# ipro7 register map
Vendor: intelpro; Series: BTBLE
CPU: ipro7, little endian
Registers are 32-bit, read-write, reset 0x0 unless marked. A register's access mark holds for its fields unless they carry their own. Offsets are from the block's base; [hi:lo] are bit positions; {n}, {i} and the like mark numbered series; 'fields as' and 'values as' point back to an identical list.

## OSD_DRAW
Base 0x30047000
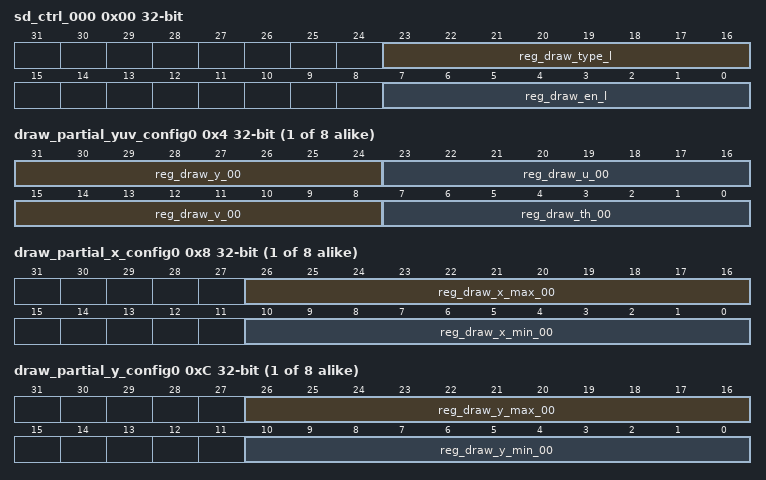
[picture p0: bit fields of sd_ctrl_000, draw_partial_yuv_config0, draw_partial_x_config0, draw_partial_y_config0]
0x00 sd_ctrl_000
  [23:16] reg_draw_type_l — Config of all layers draw type in OSD draw. MSB layer has the highest priority, LSB layer has the lowest priority. Value '1' means SOLID type, '0' means HOLLOW type.
  [7:0] reg_draw_en_l — Enable or disable draw of all layers in OSD draw. MSB layer has the highest priority, LSB layer has the lowest priority. Value '1' means enable, '0' means disable.
{0x4+0xC*i} draw_partial_yuv_config{i} (i=0..7)
  [31:24] reg_draw_y_{i:02} — Y component of draw layer{i} in OSD draw.. Range:0~255
  [23:16] reg_draw_u_{i:02} — U component of draw layer{i} in OSD draw.. Range:0~255
  [15:8] reg_draw_v_{i:02} — V component of draw layer{i} in OSD draw.. Range:0~255
  [7:0] reg_draw_th_{i:02} — Thickness of line of draw layer{i} in OSD draw.. Range:0~255. MUST be EVEN
{0x8+0xC*i} draw_partial_x_config{i} (i=0..7)
  [26:16] reg_draw_x_max_{i:02} — End X point of draw layer{i} in OSD draw.. MUST be ODD
  [10:0] reg_draw_x_min_{i:02} — Start X point of draw layer{i} in OSD draw.. MUST be EVEN
{0xC+0xC*i} draw_partial_y_config{i} (i=0..7)
  [26:16] reg_draw_y_max_{i:02} — End Y point of draw layer{i} in OSD draw.. MUST be ODD
  [10:0] reg_draw_y_min_{i:02} — Start Y point of draw layer{i} in OSD draw.. MUST be EVEN
0xF0 draw_sw_shd
  [0] cr_sw_shd

## WDR
Base 0x3004E000
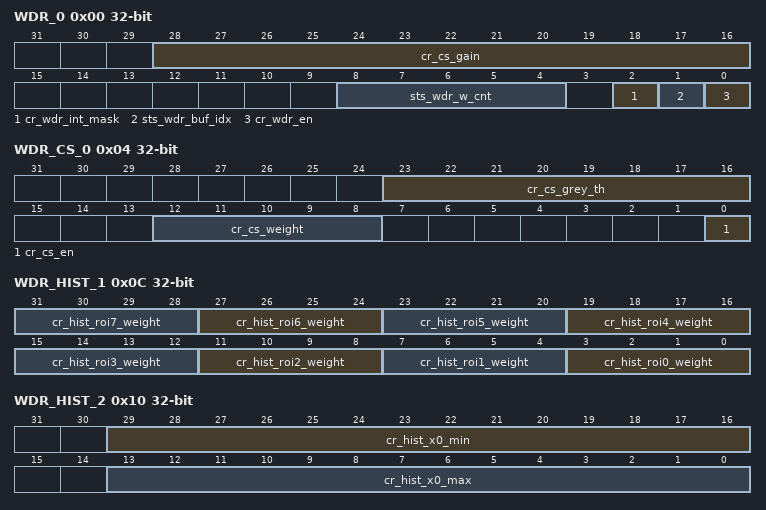
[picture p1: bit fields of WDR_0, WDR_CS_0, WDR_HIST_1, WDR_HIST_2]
0x00 WDR_0 (reset mask 0xFFFFFE0D)
  [28:16] cr_cs_gain — chroma suppression gain
  [8:4] sts_wdr_w_cnt ro — write buf index
  [2] cr_wdr_int_mask — Interrupt mask
  [1] sts_wdr_buf_idx ro — read buf index
  [0] cr_wdr_en — 0' - disable wdr, '1' -enable
0x04 WDR_CS_0
  [23:16] cr_cs_grey_th — chroma suppression grey threshold
  [12:8] cr_cs_weight — chroma suppression weight
  [0] cr_cs_en — 0' - disable chroma suppression, '1' -enable
0x08 WDR_HIST_0
  [7:0] cr_hist_roi_en — enable histogram of ROI 7-0
0x0C WDR_HIST_1
  [4n+3:4n] cr_hist_roi{n}_weight (n=0..7) — weight of ROI {n}
0x10 WDR_HIST_2
  [29:16] cr_hist_x0_min — left 1alue of x axis in ROI 0
  [13:0] cr_hist_x0_max — right 1alue of x axis in ROI 0
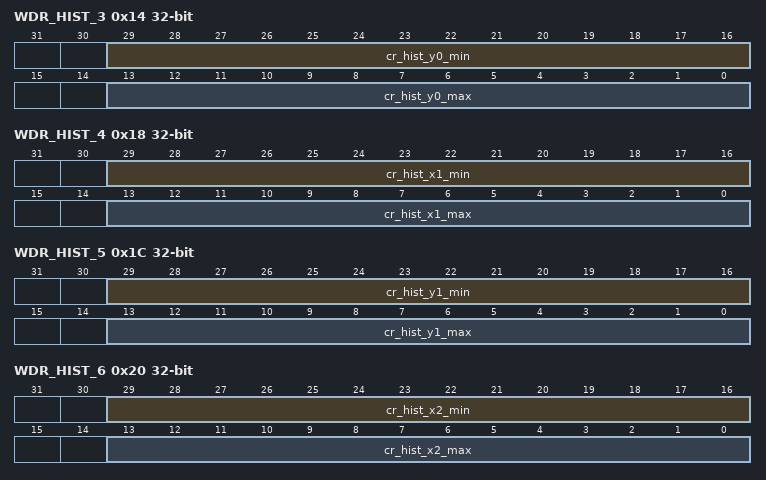
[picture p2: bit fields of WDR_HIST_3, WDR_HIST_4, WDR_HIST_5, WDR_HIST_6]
0x14 WDR_HIST_3
  [29:16] cr_hist_y0_min — bottom 1alue of x axis in ROI 0
  [13:0] cr_hist_y0_max — top 1alue of x axis in ROI 0
0x18 WDR_HIST_4
  [29:16] cr_hist_x1_min — left 1alue of x axis in ROI 1
  [13:0] cr_hist_x1_max — right 1alue of x axis in ROI 1
0x1C WDR_HIST_5
  [29:16] cr_hist_y1_min — bottom 1alue of x axis in ROI 1
  [13:0] cr_hist_y1_max — top 1alue of x axis in ROI 1
0x20 WDR_HIST_6
  [29:16] cr_hist_x2_min — left 1alue of x axis in ROI 2
  [13:0] cr_hist_x2_max — right 1alue of x axis in ROI 2
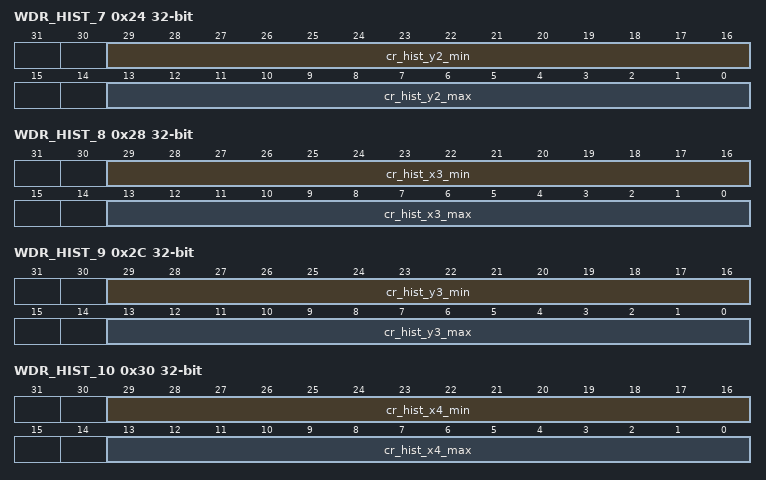
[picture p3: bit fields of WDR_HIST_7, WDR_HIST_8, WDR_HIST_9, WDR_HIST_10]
0x24 WDR_HIST_7
  [29:16] cr_hist_y2_min — bottom 1alue of x axis in ROI 2
  [13:0] cr_hist_y2_max — top 1alue of x axis in ROI 2
0x28 WDR_HIST_8
  [29:16] cr_hist_x3_min — left 1alue of x axis in ROI 3
  [13:0] cr_hist_x3_max — right 1alue of x axis in ROI 3
0x2C WDR_HIST_9
  [29:16] cr_hist_y3_min — bottom 1alue of x axis in ROI 3
  [13:0] cr_hist_y3_max — top 1alue of x axis in ROI 3
0x30 WDR_HIST_10
  [29:16] cr_hist_x4_min — left 1alue of x axis in ROI 4
  [13:0] cr_hist_x4_max — right 1alue of x axis in ROI 4
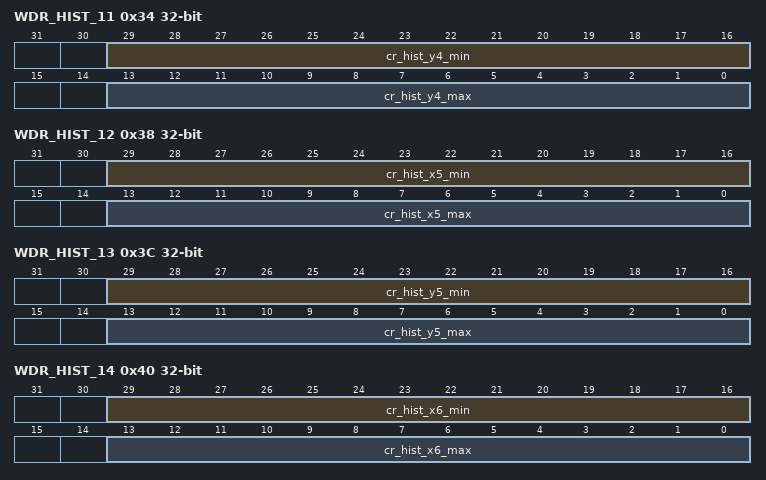
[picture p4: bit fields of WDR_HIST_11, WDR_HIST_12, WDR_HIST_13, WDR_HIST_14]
0x34 WDR_HIST_11
  [29:16] cr_hist_y4_min — bottom 1alue of x axis in ROI 4
  [13:0] cr_hist_y4_max — top 1alue of x axis in ROI 4
0x38 WDR_HIST_12
  [29:16] cr_hist_x5_min — left 1alue of x axis in ROI 5
  [13:0] cr_hist_x5_max — right 1alue of x axis in ROI 5
0x3C WDR_HIST_13
  [29:16] cr_hist_y5_min — bottom 1alue of x axis in ROI 5
  [13:0] cr_hist_y5_max — top 1alue of x axis in ROI 5
0x40 WDR_HIST_14
  [29:16] cr_hist_x6_min — left 1alue of x axis in ROI 6
  [13:0] cr_hist_x6_max — right 1alue of x axis in ROI 6
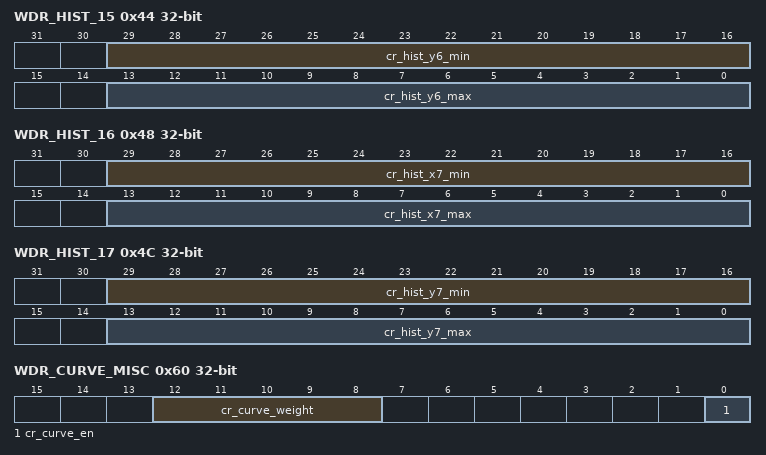
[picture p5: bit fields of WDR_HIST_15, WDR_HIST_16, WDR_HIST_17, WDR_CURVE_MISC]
0x44 WDR_HIST_15
  [29:16] cr_hist_y6_min — bottom 1alue of x axis in ROI 6
  [13:0] cr_hist_y6_max — top 1alue of x axis in ROI 6
0x48 WDR_HIST_16
  [29:16] cr_hist_x7_min — left 1alue of x axis in ROI 7
  [13:0] cr_hist_x7_max — right 1alue of x axis in ROI 7
0x4C WDR_HIST_17
  [29:16] cr_hist_y7_min — bottom 1alue of x axis in ROI 7
  [13:0] cr_hist_y7_max — top 1alue of x axis in ROI 7
0x60 WDR_CURVE_MISC
  [12:8] cr_curve_weight — wdr curve weight
  [0] cr_curve_en — enable wdr curve
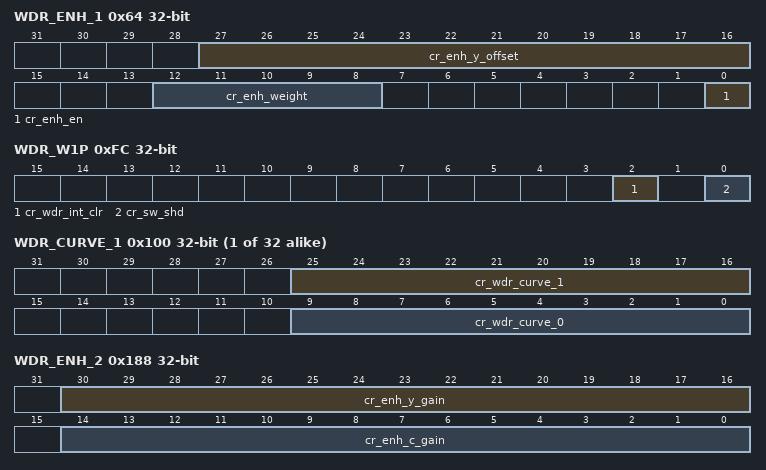
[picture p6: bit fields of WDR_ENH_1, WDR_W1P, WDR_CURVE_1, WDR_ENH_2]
0x64 WDR_ENH_1
  [27:16] cr_enh_y_offset — luma offset of post enhancement
  [12:8] cr_enh_weight — post enhancement weight
  [0] cr_enh_en — enable post enhancement
0xFC WDR_W1P
  [2] cr_wdr_int_clr wo — WDR interrupt clear
  [0] cr_sw_shd wo — SW force shadow
{0xFC+4i} WDR_CURVE_{i} (i=1..32)
  [25:16] cr_wdr_curve_{2i-1} — wdr curve {2i-1}
  [9:0] cr_wdr_curve_{2i-2} — wdr curve {2i-2}
0x188 WDR_ENH_2
  [30:16] cr_enh_y_gain — luma gain of post enhancement
  [14:0] cr_enh_c_gain — chroma gain of post enhancement

## AE_HIST
Base 0x3004C000
{0x800+4i} REG_HIST0_{i} (reset mask 0xFF000000) (i=0..64)
  [23:0] sts_wdr_hist0_{i} ro — ping-pong reg0 of histogram {i}
{0xA00+4i} REG_HIST1_{i} (reset mask 0xFF000000) (i=0..64)
  [23:0] sts_wdr_hist1_{i} ro — ping-pong reg1 of histogram {i}

## GAMMA
Base 0x3004F000
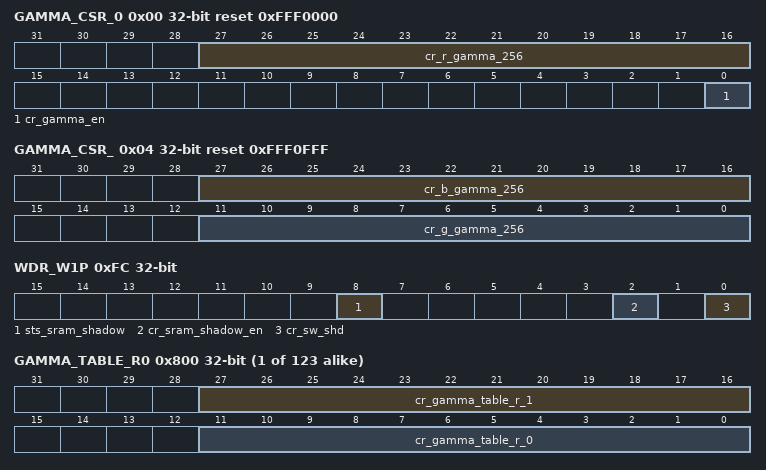
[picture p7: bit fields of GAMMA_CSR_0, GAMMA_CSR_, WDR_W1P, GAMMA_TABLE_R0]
0x00 GAMMA_CSR_0 reset 0xFFF0000
  [27:16] cr_r_gamma_256 — R-channel gamma table
  [0] cr_gamma_en — 1'b0 - disable gamma 1'b1 - enable gamma
0x04 GAMMA_CSR_ reset 0xFFF0FFF
  [27:16] cr_b_gamma_256 — B-channel gamma table
  [11:0] cr_g_gamma_256 — G-channel gamma table
0xFC WDR_W1P (reset mask 0xFFFFFEFF)
  [8] sts_sram_shadow ro — State sram shadow
  [2] cr_sram_shadow_en wo
  [0] cr_sw_shd wo — SW force shadow
{0x800+4i} GAMMA_TABLE_R{i} (i=0..122)
  [27:16] cr_gamma_table_r_{2i+1} — gamma table value
  [11:0] cr_gamma_table_r_{2i} — gamma table value
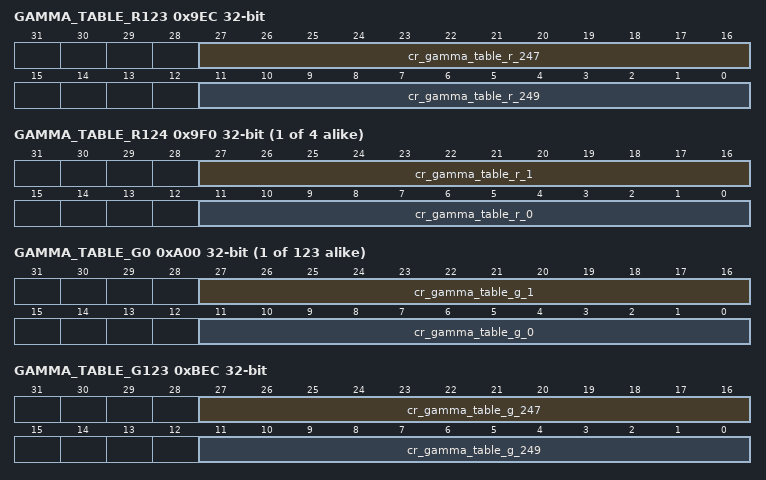
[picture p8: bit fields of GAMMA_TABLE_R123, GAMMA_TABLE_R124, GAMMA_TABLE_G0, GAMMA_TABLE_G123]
0x9EC GAMMA_TABLE_R123
  [27:16] cr_gamma_table_r_247 — gamma table value
  [11:0] cr_gamma_table_r_249 — gamma table value
{0x800+4i} GAMMA_TABLE_R{i} (i=124..127)
  fields as GAMMA_TABLE_R0
{0xA00+4i} GAMMA_TABLE_G{i} (i=0..122)
  [27:16] cr_gamma_table_g_{2i+1} — gamma table value
  [11:0] cr_gamma_table_g_{2i} — gamma table value
0xBEC GAMMA_TABLE_G123
  [27:16] cr_gamma_table_g_247 — gamma table value
  [11:0] cr_gamma_table_g_249 — gamma table value
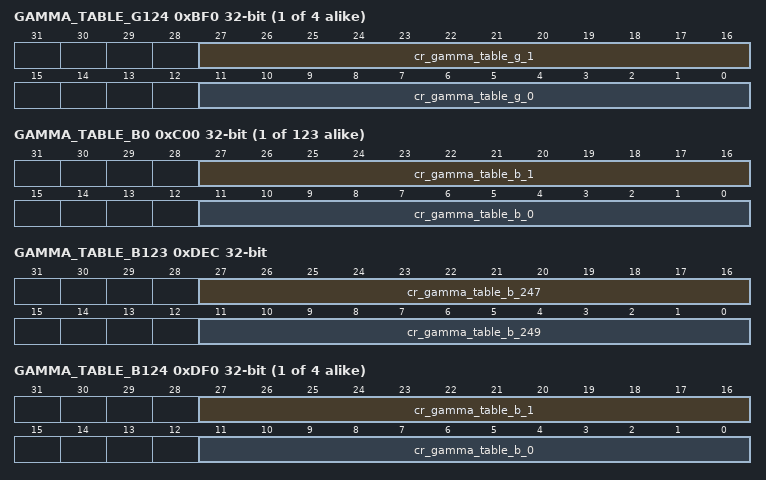
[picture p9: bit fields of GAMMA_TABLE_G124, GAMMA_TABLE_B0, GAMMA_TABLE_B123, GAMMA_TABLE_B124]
{0xA00+4i} GAMMA_TABLE_G{i} (i=124..127)
  fields as GAMMA_TABLE_G0
{0xC00+4i} GAMMA_TABLE_B{i} (i=0..122)
  [27:16] cr_gamma_table_b_{2i+1} — gamma table value
  [11:0] cr_gamma_table_b_{2i} — gamma table value
0xDEC GAMMA_TABLE_B123
  [27:16] cr_gamma_table_b_247 — gamma table value
  [11:0] cr_gamma_table_b_249 — gamma table value
{0xC00+4i} GAMMA_TABLE_B{i} (i=124..127)
  fields as GAMMA_TABLE_B0
